VERSION ""

NS_ :

BS_:

BU_:

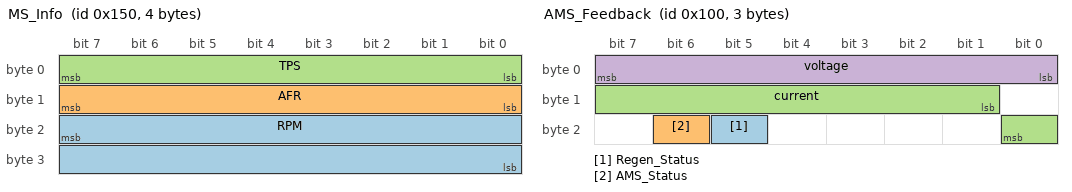
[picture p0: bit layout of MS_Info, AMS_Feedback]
BO_ 336 MS_Info: 4 Vector__XXX
 SG_ RPM : 23|16@0+ (1,0) [0|65535] "" Vector__XXX
 SG_ AFR : 15|8@0+ (1,0) [0|255] "" Vector__XXX
 SG_ TPS : 7|8@0+ (1,0) [0|255] "" Vector__XXX

BO_ 256 AMS_Feedback: 3 Vector__XXX
 SG_ Regen_Status : 21|1@0+ (1,0) [0|1] "" Vector__XXX
 SG_ AMS_Status : 22|1@0+ (1,0) [0|1] "" Vector__XXX
 SG_ current : 9|8@1- (1,0) [-128|127] "" Vector__XXX
 SG_ voltage : 7|8@0+ (1,0) [0|255] "" Vector__XXX
